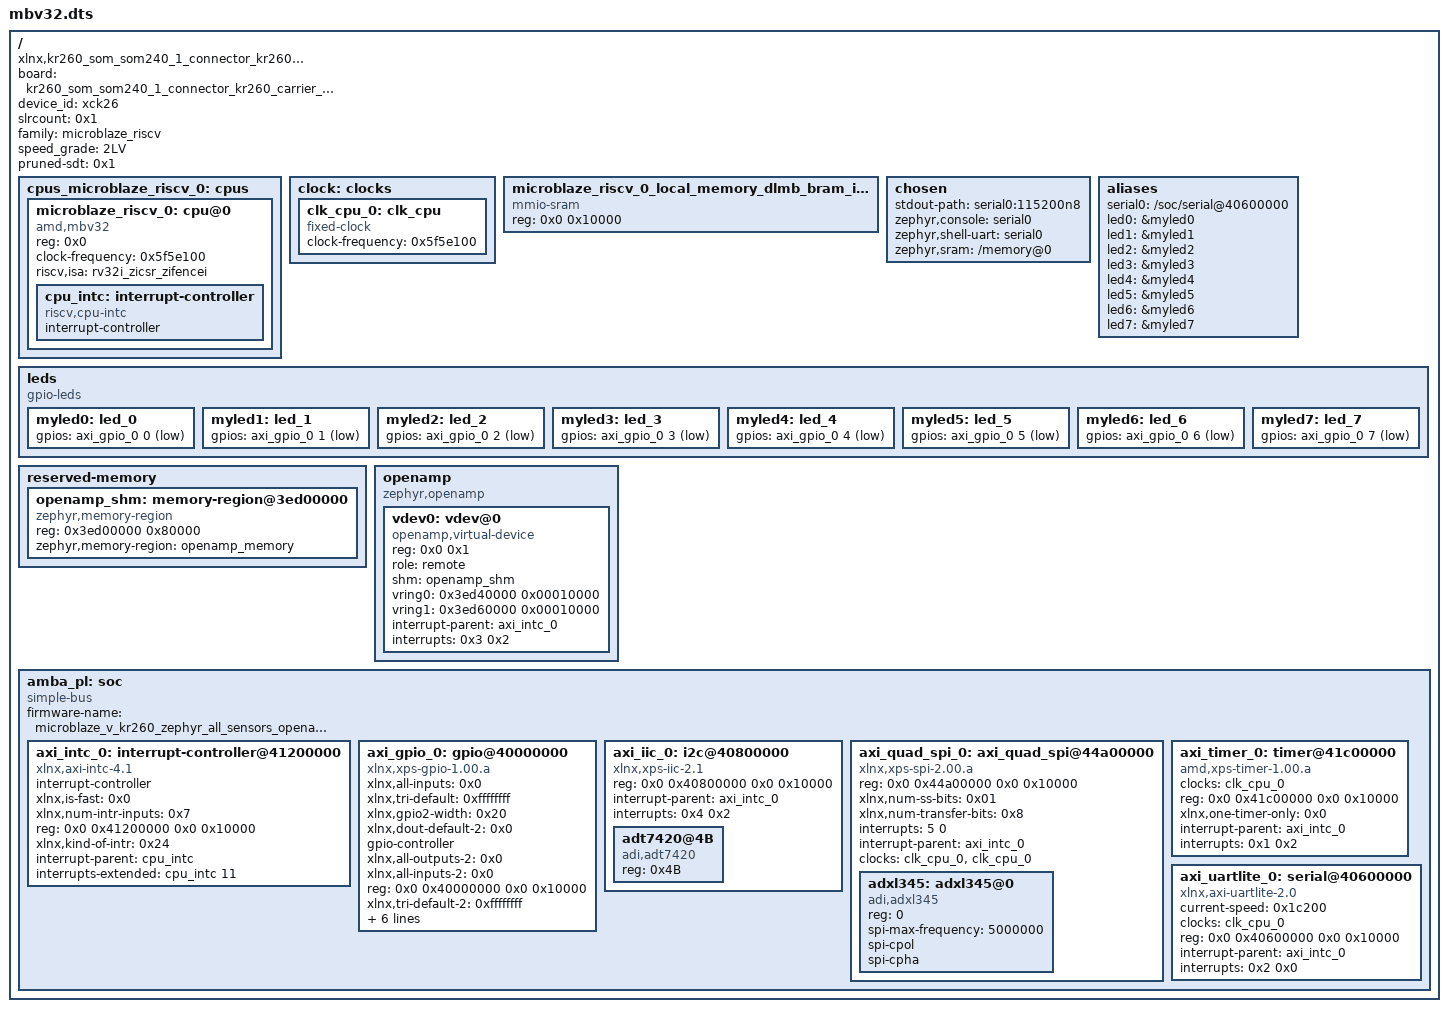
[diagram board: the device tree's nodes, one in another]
/dts-v1/;

#include "dt-bindings/gpio/gpio.h"

/ {
        board = "kr260_som_som240_1_connector_kr260_carrier_som240_1_connector_som240_2_connector_kr260_carrier_som240_2_connector";
        compatible = "xlnx,kr260_som_som240_1_connector_kr260_carrier_som240_1_connector_som240_2_connector_kr260_carrier_som240_2_connector";
        device_id = "xck26";
        slrcount = <0x1>;
        #address-cells = <0x1>;
        #size-cells = <0x1>;
        family = "microblaze_riscv";
        speed_grade = "2LV";
        pruned-sdt = <0x1>;

        cpus_microblaze_riscv_0: cpus {
                #cpu-mask-cells = <0x1>;
                #address-cells = <0x1>;
                #size-cells = <0x0>;
                #ranges-address-cells = <0x1>;
                #ranges-size-cells = <0x1>;
                phandle = <0xb>;

                microblaze_riscv_0: cpu@0 {
                        reg = <0x0>;
                        clock-frequency = <0x5f5e100>;
                        compatible = "amd,mbv32", "riscv";
                        device_type = "cpu";
                        riscv,isa = "rv32i_zicsr_zifencei";
                        phandle = <0x3>;

                        cpu_intc: interrupt-controller {
                                compatible = "riscv,cpu-intc";
                                interrupt-controller;
                                #interrupt-cells = <0x1>;
                                phandle = <0xe>;
                        };
                };
        };

        clock: clocks {
                #address-cells = <0x1>;
                #size-cells = <0x0>;
                phandle = <0xd>;

                clk_cpu_0: clk_cpu {
                        compatible = "fixed-clock";
                        clock-frequency = <0x5f5e100>;
                        #clock-cells = <0x0>;
                        phandle = <0xa>;
                };
        };

        microblaze_riscv_0_local_memory_dlmb_bram_if_cntlr_memory: memory@0 {
                compatible = "mmio-sram";
                device_type = "memory";
                reg = <0x0 0x10000>;
                phandle = <0x1>;
        };

        chosen {
                stdout-path = "serial0:115200n8";
                zephyr,console = "serial0";
                zephyr,shell-uart = "serial0";
                zephyr,sram = "/memory@0";
        };

        aliases {
                serial0 = "/soc/serial@40600000";
                led0 = &myled0;
                led1 = &myled1;
                led2 = &myled2;
                led3 = &myled3;
                led4 = &myled4;
                led5 = &myled5;
                led6 = &myled6;
                led7 = &myled7;
        };
        
        leds {
   		compatible = "gpio-leds";
   		myled0: led_0 {
   			gpios = <&axi_gpio_0 0 GPIO_ACTIVE_LOW>;
                };
               	myled1: led_1 {
   			gpios = <&axi_gpio_0 1 GPIO_ACTIVE_LOW>;
                };
                myled2: led_2 {
   			gpios = <&axi_gpio_0 2 GPIO_ACTIVE_LOW>;
                };
                myled3: led_3 {
   			gpios = <&axi_gpio_0 3 GPIO_ACTIVE_LOW>;
                };
                myled4: led_4 {
   			gpios = <&axi_gpio_0 4 GPIO_ACTIVE_LOW>;
                };
                myled5: led_5 {
   			gpios = <&axi_gpio_0 5 GPIO_ACTIVE_LOW>;
                };
                myled6: led_6 {
   			gpios = <&axi_gpio_0 6 GPIO_ACTIVE_LOW>;
                };
                myled7: led_7 {
   			gpios = <&axi_gpio_0 7 GPIO_ACTIVE_LOW>;
                };
   	};
	
	reserved-memory {
		#address-cells = <1>;
		#size-cells = <1>;
		ranges;

		openamp_shm: memory-region@3ed00000 {
			compatible = "zephyr,memory-region";
			reg = <0x3ed00000 0x80000>; /* 512 KB PS DDR for OpenAMP */
			zephyr,memory-region = "openamp_memory";
		};
	};
   	
   	//need to modify reg values
   	openamp {
   		#size-cells = <0x1>;
                #address-cells = <0x1>;
	    	compatible = "zephyr,openamp";
	    	status = "okay";

	    vdev0: vdev@0 {
		compatible = "openamp,virtual-device";
		reg = <0x0 0x1>;
		role = "remote";

		shm = <&openamp_shm>;
		vring0 = <0x3ed40000 0x00010000>;
		vring1 = <0x3ed60000 0x00010000>;

		interrupt-parent = <&axi_intc_0>;
		interrupts = <0x3 0x2>;
	    };
	};
	   	
   	// may need to re-check reg
   	/*
   	reserved-memory {
		#address-cells = <2>;
		#size-cells = <2>;
		ranges;
		rproc_0_reserved: rproc@3ed000000 {
			no-map;
			reg = <0x0 0x3ed00000 0x0 0x1000000>;
		};
		microblaze_text_data: microblaze:@70000000 {
			no-map;
			reg = <0x0 0x70000000 0x0 0x80000>;
		};
	};

	
	amba {
		vring: vring@0 {
			compatible = "vring_uio";
			reg = <0x0 0x3ed40000 0x0 0x40000>;
		};
		shm0: shm@0 {
			compatible = "shm_uio";
			reg = <0x0 0x3ed20000 0x0 0x0100000>;
		};
		shm1: shm@1 {
			compatible = "shm_uio";
			reg = <0x0 0x3ee40000 0x0 0x0100000>;
		};
	};
*/

        amba_pl: soc {
                phandle = <0x9>;
                firmware-name = "microblaze_v_kr260_zephyr_all_sensors_openamp.bit.bin";
                #size-cells = <0x2>;
                #address-cells = <0x2>;
                compatible = "simple-bus";
                ranges;

                axi_intc_0: interrupt-controller@41200000 {
                        interrupt-controller;
                        xlnx,is-fast = <0x0>;
                        xlnx,num-intr-inputs = <0x7>;
                        reg = <0x0 0x41200000 0x0 0x10000>;
                        compatible = "xlnx,axi-intc-4.1", "xlnx,xps-intc-1.00.a";
                        xlnx,kind-of-intr = <0x24>;
                        #interrupt-cells = <0x2>;
                        phandle = <0x2>;
                        interrupt-parent = <&cpu_intc>;
                        interrupts-extended = <&cpu_intc 11>;
                };

                axi_gpio_0: gpio@40000000 {
                        xlnx,all-inputs = <0x0>;
                        xlnx,tri-default = <0xffffffff>;
                        xlnx,gpio2-width = <0x20>;
                        xlnx,dout-default-2 = <0x0>;
                        gpio-controller;
                        xlnx,all-outputs-2 = <0x0>;
                        xlnx,all-inputs-2 = <0x0>;
                        reg = <0x0 0x40000000 0x0 0x10000>;
                        xlnx,tri-default-2 = <0xffffffff>;
                        xlnx,is-dual = <0x0>;
                        xlnx,dout-default = <0x0>;
                        interrupt-parent = <&axi_intc_0>;
                        xlnx,gpio-width = <0x8>;
                        #gpio-cells = <0x2>;
                        xlnx,all-outputs = <0x0>;
                        compatible = "xlnx,xps-gpio-1.00.a";
                        interrupts = <0x6 0x2>;
                        phandle = <0x4>;
                };

                axi_iic_0: i2c@40800000 {
                        #size-cells = <0x0>;
                        #address-cells = <0x1>;
                        reg = <0x0 0x40800000 0x0 0x10000>;
                        interrupt-parent = <&axi_intc_0>;
                        compatible = "xlnx,xps-iic-2.1";
                        interrupts = <0x4 0x2>;
                        status = "okay";
                        phandle = <0x5>;
                        
                        adt7420@4B {
                                reg = <0x4B>;
                                compatible = "adi,adt7420";
                        };
                };
                
                axi_quad_spi_0: axi_quad_spi@44a00000 {
			#address-cells = <1>;
			#size-cells = <0>;
			compatible = "xlnx,xps-spi-2.00.a"; /*essayer avec compatible = "xlnx,xps-iic-2.1";*/
			reg = <0x0 0x44a00000 0x0 0x10000>;
			xlnx,num-ss-bits = <0x01>;
			xlnx,num-transfer-bits = <0x8>;
			interrupts = < 5 0 >;
			interrupt-parent = <&axi_intc_0>;
			clocks = <&clk_cpu_0>, <&clk_cpu_0>;  /*essayer avec clocks = <&clk_cpu_0>;*/
			status = "okay";
			
			adxl345: adxl345@0 {
				compatible = "adi,adxl345";
				/* SPI chip select 0 selects hardware CS0 on the AXI SPI IP*/ 
				/*if we wanted to use multiple spi devices we would need to use also CS1, CS2... so reg = <1>;   reg = <2>; ...*/
				reg = <0>;                   
				spi-max-frequency = <5000000>;  /* 5 MHz max */
				spi-cpol;
				spi-cpha;
			};
		};

                axi_timer_0: timer@41c00000 {
                        clocks = <&clk_cpu_0>;
                        reg = <0x0 0x41c00000 0x0 0x10000>;
                        xlnx,one-timer-only = <0x0>;
                        interrupt-parent = <&axi_intc_0>;
                        compatible = "amd,xps-timer-1.00.a";
                        interrupts = <0x1 0x2>;
                        phandle = <0x6>;
                };

                axi_uartlite_0: serial@40600000 {
                        current-speed = <0x1c200>;
                        clocks = <&clk_cpu_0>;
                        reg = <0x0 0x40600000 0x0 0x10000>;
                        interrupt-parent = <&axi_intc_0>;
                        compatible = "xlnx,axi-uartlite-2.0", "xlnx,xps-uartlite-1.00.a";
                        interrupts = <0x2 0x0>;
                        phandle = <0x7>;
                };
        };
};
